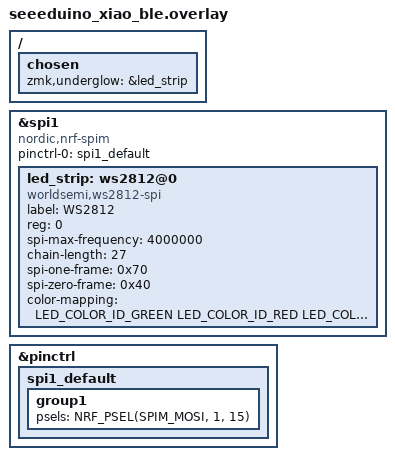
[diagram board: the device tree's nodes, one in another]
#include <dt-bindings/led/led.h>
#include <dt-bindings/pinctrl/nrf-pinctrl.h>

/ {
    chosen {
        zmk,underglow = &led_strip;
    };
};

&spi1 {
    compatible = "nordic,nrf-spim";
    status = "okay";
    
    pinctrl-0 = <&spi1_default>;
    pinctrl-names = "default";

    led_strip: ws2812@0 {
        compatible = "worldsemi,ws2812-spi";
        label = "WS2812";

        /* SPI */
        reg = <0>; /* ignored, but necessary for SPI */
        spi-max-frequency = <4000000>;

        /* WS2812 */
        chain-length = <27>; /* arbitrary; change at will */
        spi-one-frame = <0x70>;
        spi-zero-frame = <0x40>;

        color-mapping = <LED_COLOR_ID_GREEN LED_COLOR_ID_RED LED_COLOR_ID_BLUE>;
    };
};

&pinctrl {
    spi1_default: spi1_default {
        group1 {
            psels = <NRF_PSEL(SPIM_MOSI, 1, 15)>;
        };
    };
}; 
